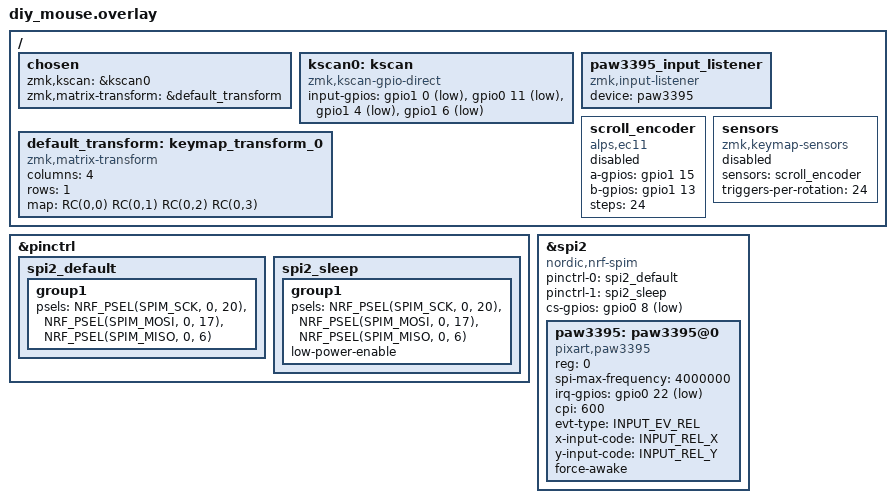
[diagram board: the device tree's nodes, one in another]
#include <dt-bindings/zmk/matrix_transform.h>
#include <dt-bindings/gpio/gpio.h>
#include <zephyr/dt-bindings/input/input-event-codes.h>
#include <zephyr/dt-bindings/pinctrl/nrf-pinctrl.h>

/ {
    chosen {
        zmk,kscan = &kscan0;
        zmk,matrix-transform = &default_transform;
    };

    kscan0: kscan {
        compatible = "zmk,kscan-gpio-direct";
        input-gpios
            = <&gpio1 0 (GPIO_ACTIVE_LOW | GPIO_PULL_UP)>   /* D6 / P1.00 */
            , <&gpio0 11 (GPIO_ACTIVE_LOW | GPIO_PULL_UP)>  /* D7 / P0.11 */
            , <&gpio1 4 (GPIO_ACTIVE_LOW | GPIO_PULL_UP)>   /* D8 / P1.04 */
            , <&gpio1 6 (GPIO_ACTIVE_LOW | GPIO_PULL_UP)>   /* D9 / P1.06 */
            ;
    };

    default_transform: keymap_transform_0 {
        compatible = "zmk,matrix-transform";
        columns = <4>;
        rows = <1>;
        map = <
            RC(0,0) RC(0,1) RC(0,2) RC(0,3)
        >;
    };

    paw3395_input_listener: paw3395_input_listener {
        compatible = "zmk,input-listener";
        status = "okay";
        device = <&paw3395>;
    };

    scroll_encoder: scroll_encoder {
        compatible = "alps,ec11";
        a-gpios = <&gpio1 15 (GPIO_ACTIVE_HIGH | GPIO_PULL_UP)>; /* D18 / P1.15 / Encoder A */
        b-gpios = <&gpio1 13 (GPIO_ACTIVE_HIGH | GPIO_PULL_UP)>; /* D15 / P1.13 / Encoder B */
        steps = <24>;
        status = "disabled";
    };

    sensors: sensors {
        compatible = "zmk,keymap-sensors";
        status = "disabled";
        sensors = <&scroll_encoder>;
        triggers-per-rotation = <24>;
    };
};

&pinctrl {
    spi2_default: spi2_default {
        group1 {
            psels = <NRF_PSEL(SPIM_SCK, 0, 20)>,
                    <NRF_PSEL(SPIM_MOSI, 0, 17)>,
                    <NRF_PSEL(SPIM_MISO, 0, 6)>;
        };
    };

    spi2_sleep: spi2_sleep {
        group1 {
            psels = <NRF_PSEL(SPIM_SCK, 0, 20)>,
                    <NRF_PSEL(SPIM_MOSI, 0, 17)>,
                    <NRF_PSEL(SPIM_MISO, 0, 6)>;
            low-power-enable;
        };
    };
};

&spi2 {
    compatible = "nordic,nrf-spim";
    status = "okay";
    pinctrl-0 = <&spi2_default>;
    pinctrl-1 = <&spi2_sleep>;
    pinctrl-names = "default", "sleep";
    cs-gpios = <&gpio0 8 GPIO_ACTIVE_LOW>; /* D0 / P0.08 / PAW3395 nCS */

    paw3395: paw3395@0 {
        compatible = "pixart,paw3395";
        status = "okay";
        reg = <0>;
        spi-max-frequency = <4000000>;
        irq-gpios = <&gpio0 22 (GPIO_ACTIVE_LOW | GPIO_PULL_UP)>; /* D4 / P0.22 / PAW3395 MOT */
        cpi = <600>;
        evt-type = <INPUT_EV_REL>;
        x-input-code = <INPUT_REL_X>;
        y-input-code = <INPUT_REL_Y>;
        force-awake;
    };
};
